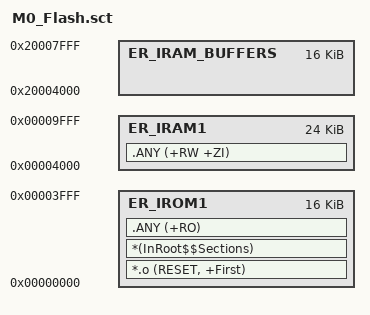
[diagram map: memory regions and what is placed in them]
; memory map assignment
; check with platform_config.h header
LR_IROM1 0x0  0x8000  {    ; load region size_region 0xA000 = 40K total

  	; 0x10080000 - 0x10084000
	ER_IROM1 0x0 0x4000  {  ; 16K code space
   
   		*.o (RESET, +First)
   		*(InRoot$$Sections)		   ; only needed if arm library included
   		.ANY (+RO)
	}

  	; 0x10084000 - 0x1008A000
	ER_IRAM1 0x4000 	0x6000 { ; 24 K data space
   		.ANY (+RW +ZI)
	}

   	ER_IRAM_BUFFERS 0x20004000 	0x4000 {
		; empty 
	}


}







